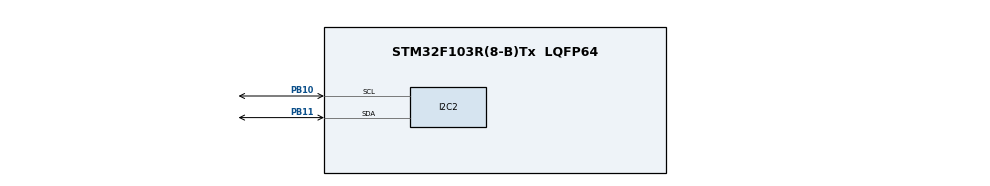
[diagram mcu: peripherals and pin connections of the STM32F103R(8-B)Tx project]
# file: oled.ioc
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Mcu.Family=STM32F1
Mcu.Name=STM32F103R(8-B)Tx
Mcu.Package=LQFP64
NVIC.PriorityGroup=NVIC_PRIORITYGROUP_4
PA13.Mode=Serial_Wire
PA13.Signal=SYS_JTMS-SWDIO
PA14.Mode=Serial_Wire
PA14.Signal=SYS_JTCK-SWCLK
PB10.Mode=I2C
PB10.Signal=I2C2_SCL
PB11.Mode=I2C
PB11.Signal=I2C2_SDA
PC14-OSC32_IN.Mode=LSE-External-Oscillator
PC14-OSC32_IN.Signal=RCC_OSC32_IN
PC15-OSC32_OUT.Mode=LSE-External-Oscillator
PC15-OSC32_OUT.Signal=RCC_OSC32_OUT
PD0-OSC_IN.Mode=HSE-External-Oscillator
PD0-OSC_IN.Signal=RCC_OSC_IN
PD1-OSC_OUT.Mode=HSE-External-Oscillator
PD1-OSC_OUT.Signal=RCC_OSC_OUT
ProjectManager.HeapSize=0x200
ProjectManager.StackSize=0x400
ProjectManager.TargetToolchain=MDK-ARM V5.27
RCC.APB1Freq_Value=8000000
RCC.APB2Freq_Value=8000000
board=custom

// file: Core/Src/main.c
/* USER CODE BEGIN Header */
/**
  ******************************************************************************
  * @file           : main.c
  * @brief          : Main program body
  ******************************************************************************
  * @attention
  *
  * <h2><center>&copy; Copyright (c) 2021 STMicroelectronics.
  * All rights reserved.</center></h2>
  *
  * This software component is licensed by ST under BSD 3-Clause license,
  * the "License"; You may not use this file except in compliance with the
  * License. You may obtain a copy of the License at:
  *                        opensource.org/licenses/BSD-3-Clause
  *
  ******************************************************************************
  */
/* USER CODE END Header */
#include "main.h"
#include "i2c.h"
#include "gpio.h"

/* USER CODE BEGIN Includes */
#include "oled.h"
/* USER CODE END Includes */

void SystemClock_Config(void);

int main(void)
{

  /* MCU Configuration--------------------------------------------------------*/

  /* Reset of all peripherals, Initializes the Flash interface and the Systick. */
  HAL_Init();

  /* Configure the system clock */
  SystemClock_Config();

  /* Initialize all configured peripherals */
  MX_GPIO_Init();
  MX_I2C2_Init();
  /* USER CODE BEGIN 2 */
  	OLED_Init();
	OLED_Clear();
	OLED_ShowString(0,0,"www.6556y.com",16);
	OLED_ShowCHinese(0,4,0);//
	OLED_ShowCHinese(16,4,7);//
	OLED_ShowCHinese(32,4,8);//
	OLED_ShowCHinese(48,4,5);//
	OLED_ShowCHinese(0,6,3);//
	OLED_ShowCHinese(16,6,4);//
	OLED_ShowCHinese(32,6,5);//
	OLED_ShowCHinese(48,6,6);//
  /* USER CODE END 2 */

  /* Infinite loop */
  while (1)
  {

  }
}

void SystemClock_Config(void)
{
  RCC_OscInitTypeDef RCC_OscInitStruct = {0};
  RCC_ClkInitTypeDef RCC_ClkInitStruct = {0};

  /** Initializes the RCC Oscillators according to the specified parameters
  * in the RCC_OscInitTypeDef structure.
  */
  RCC_OscInitStruct.OscillatorType = RCC_OSCILLATORTYPE_HSI;
  RCC_OscInitStruct.HSIState = RCC_HSI_ON;
  RCC_OscInitStruct.HSICalibrationValue = RCC_HSICALIBRATION_DEFAULT;
  RCC_OscInitStruct.PLL.PLLState = RCC_PLL_NONE;
  if (HAL_RCC_OscConfig(&RCC_OscInitStruct) != HAL_OK)
  {
    Error_Handler();
  }
  /** Initializes the CPU, AHB and APB buses clocks
  */
  RCC_ClkInitStruct.ClockType = RCC_CLOCKTYPE_HCLK|RCC_CLOCKTYPE_SYSCLK
                              |RCC_CLOCKTYPE_PCLK1|RCC_CLOCKTYPE_PCLK2;
  RCC_ClkInitStruct.SYSCLKSource = RCC_SYSCLKSOURCE_HSI;
  RCC_ClkInitStruct.AHBCLKDivider = RCC_SYSCLK_DIV1;
  RCC_ClkInitStruct.APB1CLKDivider = RCC_HCLK_DIV1;
  RCC_ClkInitStruct.APB2CLKDivider = RCC_HCLK_DIV1;

  if (HAL_RCC_ClockConfig(&RCC_ClkInitStruct, FLASH_LATENCY_0) != HAL_OK)
  {
    Error_Handler();
  }
}

void Error_Handler(void)
{
  __disable_irq();
  while (1)
  {
  }
}

/************************ (C) COPYRIGHT STMicroelectronics *****END OF FILE****/
